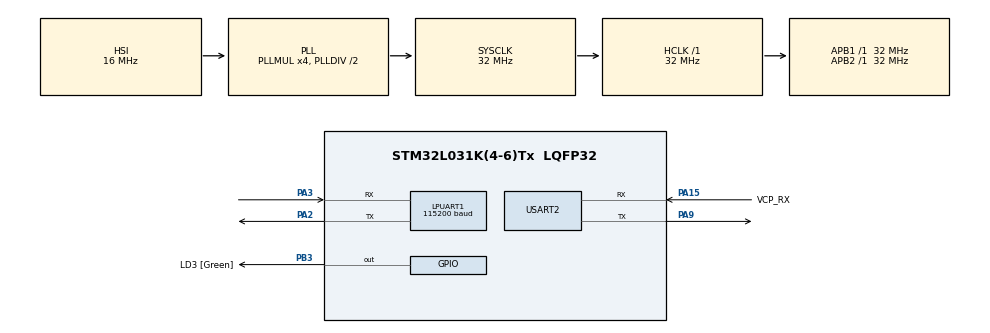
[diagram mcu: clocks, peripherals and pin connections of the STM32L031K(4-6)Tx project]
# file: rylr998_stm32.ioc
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Dma.LPUART1_RX.0.Direction=DMA_PERIPH_TO_MEMORY
Dma.LPUART1_RX.0.Instance=DMA1_Channel3
Dma.LPUART1_RX.0.MemDataAlignment=DMA_MDATAALIGN_BYTE
Dma.LPUART1_RX.0.MemInc=DMA_MINC_ENABLE
Dma.LPUART1_RX.0.Mode=DMA_NORMAL
Dma.LPUART1_RX.0.PeriphDataAlignment=DMA_PDATAALIGN_BYTE
Dma.LPUART1_RX.0.PeriphInc=DMA_PINC_DISABLE
Dma.LPUART1_RX.0.Priority=DMA_PRIORITY_LOW
Dma.LPUART1_TX.1.Direction=DMA_MEMORY_TO_PERIPH
Dma.LPUART1_TX.1.Instance=DMA1_Channel2
Dma.LPUART1_TX.1.MemDataAlignment=DMA_MDATAALIGN_BYTE
Dma.LPUART1_TX.1.MemInc=DMA_MINC_ENABLE
Dma.LPUART1_TX.1.Mode=DMA_NORMAL
Dma.LPUART1_TX.1.PeriphDataAlignment=DMA_PDATAALIGN_BYTE
Dma.LPUART1_TX.1.PeriphInc=DMA_PINC_DISABLE
Dma.LPUART1_TX.1.Priority=DMA_PRIORITY_LOW
Dma.Request0=LPUART1_RX
Dma.Request1=LPUART1_TX
Dma.Request2=USART2_RX
Dma.Request3=USART2_TX
Dma.USART2_RX.2.Direction=DMA_PERIPH_TO_MEMORY
Dma.USART2_RX.2.Instance=DMA1_Channel5
Dma.USART2_RX.2.MemDataAlignment=DMA_MDATAALIGN_BYTE
Dma.USART2_RX.2.MemInc=DMA_MINC_ENABLE
Dma.USART2_RX.2.Mode=DMA_NORMAL
Dma.USART2_RX.2.PeriphDataAlignment=DMA_PDATAALIGN_BYTE
Dma.USART2_RX.2.PeriphInc=DMA_PINC_DISABLE
Dma.USART2_RX.2.Priority=DMA_PRIORITY_LOW
Dma.USART2_TX.3.Direction=DMA_MEMORY_TO_PERIPH
Dma.USART2_TX.3.Instance=DMA1_Channel4
Dma.USART2_TX.3.MemDataAlignment=DMA_MDATAALIGN_BYTE
Dma.USART2_TX.3.MemInc=DMA_MINC_ENABLE
Dma.USART2_TX.3.Mode=DMA_NORMAL
Dma.USART2_TX.3.PeriphDataAlignment=DMA_PDATAALIGN_BYTE
Dma.USART2_TX.3.PeriphInc=DMA_PINC_DISABLE
Dma.USART2_TX.3.Priority=DMA_PRIORITY_LOW
LPUART1.BaudRate=115200
LPUART1.WordLength=UART_WORDLENGTH_8B
Mcu.Family=STM32L0
Mcu.Name=STM32L031K(4-6)Tx
Mcu.Package=LQFP32
NVIC.DMA1_Channel2_3_IRQn=true\:0\:0\:false\:false\:true\:false\:true\:true
NVIC.DMA1_Channel4_5_6_7_IRQn=true\:0\:0\:false\:false\:true\:false\:true\:true
NVIC.LPUART1_IRQn=true\:0\:0\:false\:false\:true\:true\:true\:true
NVIC.USART2_IRQn=true\:0\:0\:false\:false\:true\:true\:true\:true
PA13.GPIO_Label=TMS
PA13.Mode=Serial_Wire
PA13.Signal=SYS_SWDIO
PA14.GPIO_Label=TCK
PA14.Mode=Serial_Wire
PA14.Signal=SYS_SWCLK
PA15.GPIO_Label=VCP_RX
PA15.Mode=Asynchronous
PA15.Signal=USART2_RX
PA2.Mode=Asynchronous
PA2.Signal=LPUART1_TX
PA3.Mode=Asynchronous
PA3.Signal=LPUART1_RX
PA9.Mode=Asynchronous
PA9.Signal=USART2_TX
PB3.GPIO_Label=LD3 [Green]
PB3.Signal=GPIO_Output
PC14-OSC32_IN.Mode=LSE-External-Oscillator
PC14-OSC32_IN.Signal=RCC_OSC32_IN
PC15-OSC32_OUT.Mode=LSE-External-Oscillator
PC15-OSC32_OUT.Signal=RCC_OSC32_OUT
ProjectManager.HeapSize=0x200
ProjectManager.StackSize=0x400
ProjectManager.TargetToolchain=STM32CubeIDE
RCC.AHBFreq_Value=32000000
RCC.APB1Freq_Value=32000000
RCC.APB1TimFreq_Value=32000000
RCC.APB2Freq_Value=32000000
RCC.APB2TimFreq_Value=32000000
RCC.HCLKFreq_Value=32000000
RCC.HSE_VALUE=8000000
RCC.HSI16_VALUE=16000000
RCC.HSI48_VALUE=48000000
RCC.HSI_VALUE=16000000
RCC.MSI_VALUE=2097000
RCC.PLLMUL=RCC_PLLMUL_4
RCC.SYSCLKFreq_VALUE=32000000
RCC.SYSCLKSource=RCC_SYSCLKSOURCE_PLLCLK
RCC.VCOOutputFreq_Value=64000000
USART2.VirtualMode-Asynchronous=VM_ASYNC
board=NUCLEO-L031K6

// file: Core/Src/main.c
/* USER CODE BEGIN Header */
/**
  ******************************************************************************
  * @file           : main.c
  * @brief          : Main program body
  ******************************************************************************
  * @attention
  *
  * Copyright (c) 2025 STMicroelectronics.
  * All rights reserved.
  *
  * This software is licensed under terms that can be found in the LICENSE file
  * in the root directory of this software component.
  * If no LICENSE file comes with this software, it is provided AS-IS.
  *
  ******************************************************************************
  */
/* USER CODE END Header */
#include "main.h"
#include "dma.h"
#include "usart.h"
#include "gpio.h"

/* USER CODE BEGIN Includes */
#include "rylr998.h"
#include <string.h>

/* USER CODE END Includes */

void SystemClock_Config(void);

/* USER CODE BEGIN 0 */

void LEDBlink(GPIO_TypeDef *GPIOx, uint16_t GPIO_Pin, uint32_t delay_ms) {
    HAL_GPIO_TogglePin(GPIOx, GPIO_Pin);  // Toggle LED state
    HAL_Delay(delay_ms);                  // Wait for the delay
    HAL_GPIO_TogglePin(GPIOx, GPIO_Pin);  // Toggle LED back
    HAL_Delay(delay_ms);                  // Wait again
}

/* USER CODE END 0 */

int main(void)
{

  /* MCU Configuration--------------------------------------------------------*/

  /* Reset of all peripherals, Initializes the Flash interface and the Systick. */
   HAL_Init();

  /* Configure the system clock */
  SystemClock_Config();

  /* Initialize all configured peripherals */
  MX_GPIO_Init();
  MX_DMA_Init();
  MX_LPUART1_UART_Init();
  MX_USART2_UART_Init();
  /* USER CODE BEGIN 2 */

	//Start RX IRQ
	INIT_RX_UART2();

	//Configuration parameters
	rylr998_setChannel(1,3);

  //------------------------------
  // 		EXAMPLE SEND
  //------------------------------

	LSU_sendParameters(0,-214748364, 2147483647, 655, 65535, 10); //uint16_t destination,int32_t Lat,int32_t Lon,uint16_t T1,uint16_t T2,uint8_t bpm)

	LSU_sendSyncRequest(0);

  //------------------------------
  // 		 EXAMPLE RECIVE
  //------------------------------
  while (1){
	HAL_Delay(100);

		if(rylr998_GetInterruptFlag()){
			volatile RYLR_RX_command_t status=rylr998_prase_reciver(rx_buff,RX_BUFF);

						if(status==RYLR_RCV_ACK){
							LEDBlink(GPIOB,GPIO_PIN_3,1000);
						}
						if(status==RYLR_RCV_TIME){		          //data is in the global extern uint32_t variable :iTOW_sync
							LEDBlink(GPIOB,GPIO_PIN_3,500);
							LEDBlink(GPIOB,GPIO_PIN_3,500);
						}
						if(status== RYLR_NOT_FOUND || status==RYLR_ERR){   //va a entrar al error handler
							LEDBlink(GPIOB,GPIO_PIN_3,100);
							LEDBlink(GPIOB,GPIO_PIN_3,100);
							LEDBlink(GPIOB,GPIO_PIN_3,100);
							LEDBlink(GPIOB,GPIO_PIN_3,100);
							LEDBlink(GPIOB,GPIO_PIN_3,100);
						}
		}
}
}

void SystemClock_Config(void)
{
  RCC_OscInitTypeDef RCC_OscInitStruct = {0};
  RCC_ClkInitTypeDef RCC_ClkInitStruct = {0};
  RCC_PeriphCLKInitTypeDef PeriphClkInit = {0};

  /** Configure the main internal regulator output voltage
  */
  __HAL_PWR_VOLTAGESCALING_CONFIG(PWR_REGULATOR_VOLTAGE_SCALE1);

  /** Initializes the RCC Oscillators according to the specified parameters
  * in the RCC_OscInitTypeDef structure.
  */
  RCC_OscInitStruct.OscillatorType = RCC_OSCILLATORTYPE_HSI;
  RCC_OscInitStruct.HSIState = RCC_HSI_ON;
  RCC_OscInitStruct.HSICalibrationValue = RCC_HSICALIBRATION_DEFAULT;
  RCC_OscInitStruct.PLL.PLLState = RCC_PLL_ON;
  RCC_OscInitStruct.PLL.PLLSource = RCC_PLLSOURCE_HSI;
  RCC_OscInitStruct.PLL.PLLMUL = RCC_PLLMUL_4;
  RCC_OscInitStruct.PLL.PLLDIV = RCC_PLLDIV_2;
  if (HAL_RCC_OscConfig(&RCC_OscInitStruct) != HAL_OK)
  {
    Error_Handler();
  }

  /** Initializes the CPU, AHB and APB buses clocks
  */
  RCC_ClkInitStruct.ClockType = RCC_CLOCKTYPE_HCLK|RCC_CLOCKTYPE_SYSCLK
                              |RCC_CLOCKTYPE_PCLK1|RCC_CLOCKTYPE_PCLK2;
  RCC_ClkInitStruct.SYSCLKSource = RCC_SYSCLKSOURCE_PLLCLK;
  RCC_ClkInitStruct.AHBCLKDivider = RCC_SYSCLK_DIV1;
  RCC_ClkInitStruct.APB1CLKDivider = RCC_HCLK_DIV1;
  RCC_ClkInitStruct.APB2CLKDivider = RCC_HCLK_DIV1;

  if (HAL_RCC_ClockConfig(&RCC_ClkInitStruct, FLASH_LATENCY_1) != HAL_OK)
  {
    Error_Handler();
  }
  PeriphClkInit.PeriphClockSelection = RCC_PERIPHCLK_USART2|RCC_PERIPHCLK_LPUART1;
  PeriphClkInit.Usart2ClockSelection = RCC_USART2CLKSOURCE_PCLK1;
  PeriphClkInit.Lpuart1ClockSelection = RCC_LPUART1CLKSOURCE_PCLK1;
  if (HAL_RCCEx_PeriphCLKConfig(&PeriphClkInit) != HAL_OK)
  {
    Error_Handler();
  }
}

void Error_Handler(void){
  __disable_irq();
  while (1)
  {
  }
}
